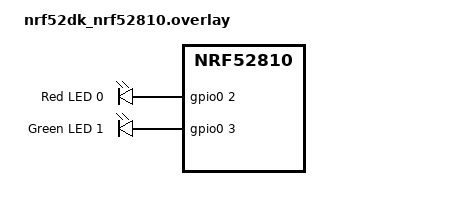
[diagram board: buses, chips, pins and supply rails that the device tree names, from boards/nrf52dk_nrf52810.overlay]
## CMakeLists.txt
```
# SPDX-License-Identifier: Apache-2.0

cmake_minimum_required(VERSION 3.20.0)

find_package(Zephyr REQUIRED HINTS $ENV{ZEPHYR_BASE})
project(rizz_hall_sensor)

FILE(GLOB app_sources
 src/main.c
 src/hall_sensor.c
 src/led_ctl.c
 src/ble.c
 src/bluetooth_adv.c
 #src/logger.c
)

target_sources(app PRIVATE
  ${app_sources}
  )

zephyr_library_include_directories(${ZEPHYR_BASE}/samples/bluetooth)
```

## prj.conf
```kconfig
# CONFIG_BT=y
# CONFIG_LOG=y
# CONFIG_BT_SMP=y
# CONFIG_BT_PERIPHERAL=y
# CONFIG_BT_DIS=y
# CONFIG_BT_DIS_PNP=n
# CONFIG_BT_BAS=y
# CONFIG_BT_HRS=y
# CONFIG_BT_DEVICE_NAME="Got dat rizz"
# CONFIG_BT_DEVICE_APPEARANCE=833
# CONFIG_LOG=y
# CONFIG_SERIAL=y
# CONFIG_CONSOLE=y
# CONFIG_UART_CONSOLE=y
# CONFIG_PRINTK=y

CONFIG_BT=y
CONFIG_BT_SMP=y
CONFIG_BT_PERIPHERAL=y
CONFIG_BT_DIS=y
CONFIG_BT_DIS_PNP=n
CONFIG_BT_BAS=y
CONFIG_BT_HRS=y
CONFIG_BT_DEVICE_NAME="Got dat rizz"
CONFIG_BT_DEVICE_APPEARANCE=833

# Drivers and peripherals
CONFIG_I2C=n
CONFIG_WATCHDOG=n
CONFIG_PINCTRL=y
CONFIG_SPI=n
CONFIG_GPIO=y
CONFIG_SERIAL=n

# Power management
CONFIG_PM=y

# Interrupts
CONFIG_DYNAMIC_INTERRUPTS=n
CONFIG_IRQ_OFFLOAD=n

# Memory protection
CONFIG_THREAD_STACK_INFO=n
CONFIG_THREAD_CUSTOM_DATA=n
CONFIG_FPU=n

# Boot
CONFIG_BOOT_BANNER=n
CONFIG_BOOT_DELAY=0

# Console
CONFIG_CONSOLE=n
CONFIG_UART_CONSOLE=n
CONFIG_STDOUT_CONSOLE=n
CONFIG_PRINTK=n
CONFIG_EARLY_CONSOLE=n

# Build
CONFIG_SIZE_OPTIMIZATIONS=y

# ARM
CONFIG_ARM_MPU=n

# In order to correctly tune the stack sizes for the threads the following
# Configurations can enabled to print the current use:
# CONFIG_THREAD_NAME=y
# CONFIG_THREAD_ANALYZER=y
# CONFIG_THREAD_ANALYZER_AUTO=y
# CONFIG_THREAD_ANALYZER_RUN_UNLOCKED=y
# CONFIG_THREAD_ANALYZER_USE_PRINTK=y
# CONFIG_THREAD_ANALYZER_AUTO_INTERVAL=20
# CONFIG_CONSOLE=y
# CONFIG_UART_CONSOLE=y
# CONFIG_SERIAL=y
# CONFIG_PRINTK=y

# Example output of thread analyzer
# BT RX               : STACK: unused 576 usage 448 / 1024 (43 %); CPU: 0 %
# BT RX pri           : STACK: unused 260 usage 188 / 448 (41 %); CPU: 0 %
# BT ECC              : STACK: unused 256 usage 888 / 1144 (77 %); CPU: 1 %
# BT TX               : STACK: unused 296 usage 344 / 640 (53 %); CPU: 0 %
# thread_analyzer     : STACK: unused 128 usage 384 / 512 (75 %); CPU: 1 %
# sysworkq            : STACK: unused 856 usage 168 / 1024 (16 %); CPU: 0 %
# logging             : STACK: unused 232 usage 536 / 768 (69 %); CPU: 0 %
# idle 00             : STACK: unused 208 usage 48 / 256 (18 %); CPU: 97 %
# main                : STACK: unused 576 usage 448 / 1024 (43 %); CPU: 0 %
CONFIG_BT_RX_STACK_SIZE=1024
CONFIG_BT_CTLR_RX_PRIO_STACK_SIZE=448
CONFIG_BT_HCI_TX_STACK_SIZE_WITH_PROMPT=y
CONFIG_BT_HCI_TX_STACK_SIZE=640
CONFIG_SYSTEM_WORKQUEUE_STACK_SIZE=512
CONFIG_IDLE_STACK_SIZE=128
CONFIG_MAIN_STACK_SIZE=640
CONFIG_ISR_STACK_SIZE=1024

# Disable features not needed
CONFIG_TIMESLICING=n
CONFIG_COMMON_LIBC_MALLOC=n
CONFIG_LOG=n
CONFIG_ASSERT=n

# Disable Bluetooth features not needed
# CONFIG_BT_DEBUG_NONE=y
CONFIG_BT_ASSERT=n
CONFIG_BT_DATA_LEN_UPDATE=n
CONFIG_BT_PHY_UPDATE=n
CONFIG_BT_GATT_CACHING=n
CONFIG_BT_GATT_SERVICE_CHANGED=n
CONFIG_BT_GAP_PERIPHERAL_PREF_PARAMS=n
CONFIG_BT_SETTINGS_CCC_LAZY_LOADING=y
CONFIG_BT_HCI_VS_EXT=n

# Disable Bluetooth controller features not needed
CONFIG_BT_CTLR_PRIVACY=n
CONFIG_BT_CTLR_PHY_2M=n

# Reduce Bluetooth buffers
CONFIG_BT_BUF_EVT_DISCARDABLE_COUNT=1
CONFIG_BT_BUF_EVT_DISCARDABLE_SIZE=45
CONFIG_BT_BUF_ACL_RX_COUNT=2
CONFIG_BT_BUF_EVT_RX_COUNT=2

CONFIG_BT_CONN_TX_MAX=2
CONFIG_BT_L2CAP_TX_BUF_COUNT=2
CONFIG_BT_CTLR_RX_BUFFERS=1
CONFIG_BT_BUF_ACL_TX_COUNT=3
CONFIG_BT_BUF_ACL_TX_SIZE=27

CONFIG_PWM=y
CONFIG_LED=y
```

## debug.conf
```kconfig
CONFIG_SERIAL=y
CONFIG_CONSOLE=y
CONFIG_UART_CONSOLE=y
CONFIG_STDOUT_CONSOLE=y
CONFIG_PRINTK=y
CONFIG_EARLY_CONSOLE=y
CONFIG_LOG=y
```

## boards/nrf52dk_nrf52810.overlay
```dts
/ {
    leds {
		compatible = "gpio-leds";
		led0: led_0 {
			gpios = <&gpio0 2 GPIO_ACTIVE_HIGH>;
			label = "Red LED 0";
		};
		led1: led_1 {
			gpios = <&gpio0 3 GPIO_ACTIVE_HIGH>;
			label = "Green LED 1";
		};
	};
};
```

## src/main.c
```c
/*
 * Copyright (c) 2024 Emunz
 *
 * All rights reserved
 */

#include <zephyr/kernel.h>
#include <zephyr/drivers/gpio.h>

#include <zephyr/logging/log.h>
LOG_MODULE_REGISTER( main, CONFIG_APP_LOG_LEVEL );

/* 1000 msec = 1 sec */
#define SLEEP_TIME_MS   1000

void boot_banner(void)
{


 	printk(" ****************************************************************************\n");
	printk("********************************************************************************\n");
	printk("*********************************# #****  *#**  #*******************************\n");
	printk("*****************************# #******# #**********  ***************************\n");
	printk("****************************   *******#  #***********   #***********************\n");
	printk("***                             #********#     #******#                      ***\n");
	printk("*********************************#    *********   ******************************\n");
	printk("****   #***#  #*****   *************   #*******#      **************************\n");
	printk("*****  #****   ********************   ********  ***   **************************\n");
	printk("*****  #***#  ******   ****  #*********  #*********   ****#  **  *****  #    ***\n");
	printk("*****       ********   **** ***    **** ***   #****   ***   ***   ****   *******\n");
	printk("*****  #**   *******   *******   ********    ******   ***   **********   *******\n");
	printk("*****  #***   ******   *****    *** ****   **** ***   ***   **********   *******\n");
	printk("***      ***    ****   ****    ##   **#    ##   ***   ****#  #*# #****   *******\n");
	printk("********************************************************************************\n");
	printk("***                                                                          ***\n");
	printk("********************************************************************************\n");
  	printk("****************************************************************************\n");
	printk("\n");
	printk("This is the fat gyatt rizzler hall effect sensor board.\n\n");

}

int main(void)
{
	LOG_INF( "Starting..." );

	return 0;
}
```

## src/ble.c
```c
/* BLE control */

/*
 * Copyright (c) 2024 Emunz
 *
 * All rights reserved
 */

#include <zephyr/types.h>
#include <zephyr/device.h>
#include <stddef.h>
#include <string.h>
#include <errno.h>
#include <zephyr/sys/byteorder.h>
#include <zephyr/kernel.h>

#include <zephyr/bluetooth/bluetooth.h>
#include <zephyr/bluetooth/hci.h>
#include <zephyr/bluetooth/conn.h>
#include <zephyr/bluetooth/uuid.h>
#include <zephyr/bluetooth/gatt.h>
#include <zephyr/bluetooth/services/bas.h>
#include <zephyr/bluetooth/services/hrs.h>

#include "bluetooth_adv.h"

#include <zephyr/logging/log.h>
LOG_MODULE_REGISTER( bluetooth, CONFIG_APP_LOG_LEVEL );

struct bt_conn* active_conn = NULL;
struct ble_adv_api* active_adv_api = NULL;

static void refresh_data_work_handler(struct k_work* work);
K_WORK_DEFINE( refresh_data_work, refresh_data_work_handler );

static void refresh_timer_handler(struct k_timer * timer_id);
K_TIMER_DEFINE(refresh_timer, refresh_timer_handler, NULL);

static inline void resume_adv_data_update(void)
{
	active_adv_api->ble_adv_handle_data_resume();
	k_timer_start( &refresh_timer, K_NO_WAIT, K_USEC( ((BT_ADV_INT_MIN >> 1) - 1) * 1000 ) );
}

static inline void terminate_adv_data_update(void)
{
	k_timer_stop( &refresh_timer );
}

static void connected(struct bt_conn *conn, uint8_t err)
{
	if (err) {
		LOG_INF("Connection failed (err 0x%02x)", err);
		active_conn = NULL;
	} else {
		LOG_INF("Connected");
		active_conn = conn;
	}

	terminate_adv_data_update();
}

static void disconnected(struct bt_conn *conn, uint8_t reason)
{
	LOG_INF("Disconnected (reason 0x%02x)", reason);
	active_conn = NULL;
	resume_adv_data_update();
}

BT_CONN_CB_DEFINE(conn_callbacks) = {
	.connected = connected,
	.disconnected = disconnected,
};

static void bt_ready(void)
{
	int err;

	LOG_INF("Bluetooth initialized");

	err = bt_le_adv_start(
						active_adv_api->advertising_params(), 
						active_adv_api->advertising_data(),
						active_adv_api->advertising_data_size(),
						NULL, 0);
	if (err) {
		LOG_INF("Advertising failed to start (err %d)", err);
		return;
	}

	LOG_INF("Advertising successfully started");

	resume_adv_data_update();
}

static void auth_cancel(struct bt_conn *conn)
{
	char addr[BT_ADDR_LE_STR_LEN];

	bt_addr_le_to_str(bt_conn_get_dst(conn), addr, sizeof(addr));

	LOG_INF("Pairing cancelled: %s", addr);
}

static struct bt_conn_auth_cb auth_cb_display = {
	.cancel = auth_cancel,
};

static void refresh_data_work_handler(struct k_work* work)
{
	active_adv_api->refresh_handler();
	bt_le_adv_update_data(
		active_adv_api->advertising_data(), 
		active_adv_api->advertising_data_size(), NULL, 0
	);
}

static void refresh_timer_handler(struct k_timer * timer_id)
{
	k_work_submit( &refresh_data_work );
}

void bt_prep_for_shutdown(void)
{
	LOG_INF("Stopping advertising...");
	if ( NULL != active_conn ) {
		(void)bt_conn_disconnect(active_conn, BT_HCI_ERR_REMOTE_POWER_OFF);
	}
	bt_le_adv_stop();
}

int bt_init(void)
{
	int err;
	size_t ble_addr_cnt = -1;
	bt_addr_le_t ble_addr;

	err = bt_enable(NULL);
	if ( 0!= err ) {
		LOG_ERR("Bluetooth init failed (err %d)", err);
		return 0;
	}

	active_adv_api = ble_adv_api_standard();
	
	err = active_adv_api->ble_adv_init();
	if ( 0 != err ) {
		LOG_ERR("Failed to initialise advertising (err %d)", err);
		return 0;
	}

	/* register the refresh handler */

	bt_ready();

	bt_conn_auth_cb_register(&auth_cb_display);

	bt_id_get(&ble_addr, &ble_addr_cnt);
	LOG_INF( "There are %d BLE addresses.", ble_addr_cnt );
	if ( 1 >= ble_addr_cnt ) {
		LOG_INF( "ble addr: %02x:%02x:%02x:%02x:%02x:%02x",
			ble_addr.a.val[5],
			ble_addr.a.val[4],
			ble_addr.a.val[3],
			ble_addr.a.val[2],
			ble_addr.a.val[1],
			ble_addr.a.val[0]
		);
	}

	return 0;
}

SYS_INIT( bt_init, APPLICATION, CONFIG_APPLICATION_INIT_PRIORITY );
```

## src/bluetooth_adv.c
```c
/* BLE standard advertising */

/*
 * Copyright (c) 2024 Emunz
 *
 * All rights reserved
 */

#include <zephyr/kernel.h>
#include <zephyr/sys/byteorder.h>
#include <zephyr/bluetooth/bluetooth.h>

#include "bluetooth_adv.h"

#include <zephyr/logging/log.h>
LOG_MODULE_REGISTER( ble_adv, CONFIG_APP_LOG_LEVEL );

#include "hall_sensor.h"

/* flags format */
/*
 *  ------------------------------------------------------------------------------- 
 * |    7    |    6    |    5    |    4    |    3    |    2    |    1    |    0    |
 *  ------------------------------------------------------------------------------- 
 * |   RSV   |   RSV   |   RSV   |   RSV   |   RSV   |       DATA VERSION          |
 *  ------------------------------------------------------------------------------- 
 * 
 * where:
 * 	RSV			 - Reseverd
 *  DATA VERSION - Payload version - starting at 0b000
 */

#define DATA_VERSION 0b000

#define MSK_DATA_VERSION 0b00000111
#define MSK_HAS_XL		 0b00100000

struct rizz_data_block {
	uint16_t manu;
	uint8_t  flags;
	uint8_t  hall_state;
} __packed;

static struct rizz_data_block rizz_ad = {
	.manu = sys_cpu_to_be16(0xffff),
	.flags = ~0,
	.hall_state = ~0,
};

static struct bt_data ad[] = {
	BT_DATA_BYTES(BT_DATA_FLAGS, (BT_LE_AD_GENERAL | BT_LE_AD_NO_BREDR)),
	BT_DATA(BT_DATA_MANUFACTURER_DATA, &rizz_ad, sizeof(rizz_ad)),
};

static struct bt_le_adv_param adv_params[] = 
	BT_LE_ADV_PARAM(BT_LE_ADV_OPT_CONNECTABLE | \
                    BT_LE_ADV_OPT_USE_NAME, \
                    BT_ADV_INT_MIN, \
                    BT_ADV_INT_MAX, NULL);

static void build_flags()
{
	rizz_ad.flags = DATA_VERSION;
}

static uint8_t refresh_handler()
{
	uint8_t ret = hall_sensor_get_state();
	rizz_ad.hall_state = ret;

	return ret;
}

static struct bt_data* advertising_data()
{
    return ad;
}

static size_t advertising_data_size()
{
    return ARRAY_SIZE(ad);
}

static struct bt_le_adv_param* advertising_params()
{
    return adv_params;
}

static void ble_adv_handle_data_resume()
{
    build_flags();
}

static int ble_adv_init()
{
    build_flags();

    return 0;
}

static struct ble_adv_api api = {
	.ble_adv_handle_data_resume = ble_adv_handle_data_resume,
	.ble_adv_init = ble_adv_init,
	.advertising_data = advertising_data,
	.advertising_data_size = advertising_data_size,
	.advertising_params = advertising_params,
	.refresh_handler = refresh_handler,
};

struct ble_adv_api* ble_adv_api_standard() {
	return &api;
}
```

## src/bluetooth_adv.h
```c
/*
 * Copyright (c) 2024 Emunz
 *
 * All rights reserved
 */

#ifndef RIZZ_BLUETOOTH_ADV_H_
#define RIZZ_BLUETOOTH_ADV_H_

#include <zephyr/bluetooth/bluetooth.h>
#include <zephyr/bluetooth/gap.h>

#define BT_ADV_INT_MIN (0x664>>2) /* 1022.5 ms */
#define BT_ADV_INT_MAX (0x780>>2) /* 1200 ms */

typedef uint8_t (*data_refresh_handler)(void);

struct ble_adv_api {
    void (*ble_adv_handle_data_resume)();
    int (*ble_adv_init)();
    struct bt_data* (*advertising_data)();
    size_t (*advertising_data_size)();
    struct bt_le_adv_param* (*advertising_params)();
    data_refresh_handler refresh_handler;
};

struct ble_adv_api* ble_adv_active_api();

/* concrete api instances for resolution */
struct ble_adv_api* ble_adv_api_standard();

#endif /* RIZZ_BLUETOOTH_ADV_H_ */
```

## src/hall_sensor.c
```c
/*
 * Copyright (c) 2024 Emunz
 *
 * All rights reserved
 */

#include "zephyr/kernel.h"
#include "zephyr/drivers/gpio.h"

#include <zephyr/logging/log.h>
LOG_MODULE_REGISTER( hall_sensor, CONFIG_APP_LOG_LEVEL );

#include "led_ctl.h"

/*
 * Get button configuration from the devicetree sw0 alias. This is mandatory.
 */
#define HALL_SW_NODE DT_ALIAS(hall_sw)
static const struct  gpio_dt_spec hall_sw = GPIO_DT_SPEC_GET(HALL_SW_NODE, gpios);
static struct        gpio_callback hall_sw_cb_data;
static uint8_t 		 hall_activated = 0;

static void hall_state_changed(const struct device *dev, struct gpio_callback *cb,
		    uint32_t pins)
{
	LOG_INF("Hall changed at %" PRIu32 "", k_cycle_get_32());
	hall_activated = (uint8_t)gpio_pin_get_dt(&hall_sw);
	led_ctl_set(LED_ID_RED, hall_activated ? 255 : 0);
}

uint8_t hall_sensor_get_state(void)
{
	return hall_activated;
}

static int hall_sensor_init(void)
{
    int ret;

	if (!gpio_is_ready_dt(&hall_sw)) {
		LOG_INF("Error: Hall switch %s is not ready", hall_sw.port->name);
		return -ENODEV;
	}

	ret = gpio_pin_configure_dt(&hall_sw, GPIO_INPUT | GPIO_PULL_UP );
	if (ret != 0) {
		LOG_INF("Error %d: failed to configure %s pin %d",
		       ret, hall_sw.port->name, hall_sw.pin);
		return -ENODEV;
	}

	ret = gpio_pin_interrupt_configure_dt(&hall_sw,
					      GPIO_INT_EDGE_BOTH);
	if (ret != 0) {
		LOG_INF("Error %d: failed to configure interrupt on %s pin %d",
			ret, hall_sw.port->name, hall_sw.pin);
		return -ENODEV;
	}

	gpio_init_callback(&hall_sw_cb_data, hall_state_changed, BIT(hall_sw.pin));
	gpio_add_callback(hall_sw.port, &hall_sw_cb_data);
	LOG_INF("Set up hall switch at %s pin %d", hall_sw.port->name, hall_sw.pin);

    return 0;
}

SYS_INIT( hall_sensor_init, APPLICATION, CONFIG_APPLICATION_INIT_PRIORITY );
```

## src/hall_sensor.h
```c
/*
 * Copyright (c) 2024 Emunz
 *
 * All rights reserved
 */

#ifndef RIZZ_HALL_SENSOR_H_
#define RIZZ_HALL_SENSOR_H_

#include <stdint.h>

uint8_t hall_sensor_get_state(void);

#endif /* RIZZ_HALL_SENSOR_H_ */
```

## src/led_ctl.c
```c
/*
 * Copyright (c) 2024 Emunz
 *
 * All rights reserved
 */

#include "zephyr/kernel.h"
#include "zephyr/drivers/gpio.h"

#include <zephyr/logging/log.h>
LOG_MODULE_REGISTER( led_ctl, CONFIG_APP_LOG_LEVEL );

#include "led_ctl.h"

#define LED0_NODE DT_ALIAS(led0)
#define LED1_NODE DT_ALIAS(led1)

static const struct gpio_dt_spec led0 = GPIO_DT_SPEC_GET(LED0_NODE, gpios);
static const struct gpio_dt_spec led1 = GPIO_DT_SPEC_GET(LED1_NODE, gpios);

static const struct gpio_dt_spec* leds[] = {
	&led0,
	&led1,
};

static int leds_init(void)
{
    if (!gpio_is_ready_dt(&led0)) {
		return -ENODEV;
	}
    if (!gpio_is_ready_dt(&led1)) {
		return -ENODEV;
	}

    return 0;
}



int led_ctl_set( enum led_id id, uint8_t intensity )
{
	if ( id >= LED_ID_Count ) {
		return -EINVAL;
	}

	gpio_flags_t target_lvl = 0 == intensity ? GPIO_OUTPUT_INACTIVE : GPIO_OUTPUT_ACTIVE;

	(void)gpio_pin_configure_dt(leds[id], target_lvl);

	return 0;
}

SYS_INIT( leds_init, APPLICATION, CONFIG_APPLICATION_INIT_PRIORITY );
```

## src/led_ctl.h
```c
/*
 * Copyright (c) 2024 Emunz
 *
 * All rights reserved
 */

#ifndef RIZZ_LED_CTL_H_
#define RIZZ_LED_CTL_H_

#include "stdint.h"

enum led_id {
    LED_ID_RED,
    LED_ID_ORANGE,

    LED_ID_Count,
};

int led_ctl_set( enum led_id id, uint8_t intensity );

#endif /* RIZZ_LED_CTL_H_ */
```
